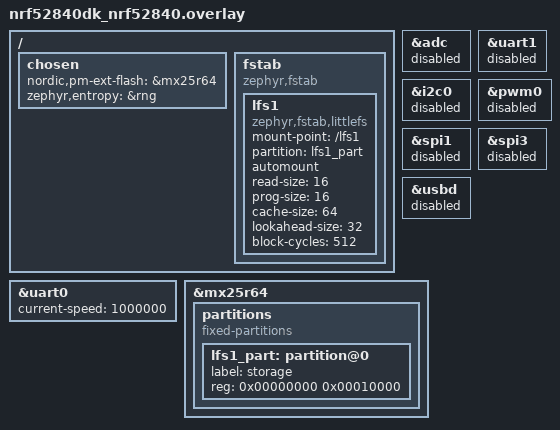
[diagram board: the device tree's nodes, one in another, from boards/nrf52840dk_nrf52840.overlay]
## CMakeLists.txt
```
#
# Copyright (c) 2021 Nordic Semiconductor ASA
#
# SPDX-License-Identifier: LicenseRef-Nordic-5-Clause
#

cmake_minimum_required(VERSION 3.20.0)

# Set Kconfig root files that will be processed as a first Kconfig for used child images.
set(mcuboot_KCONFIG_ROOT "\\\${ZEPHYR_CONNECTEDHOMEIP_MODULE_DIR}/config/nrfconnect/chip-module/Kconfig.mcuboot.root")
set(multiprotocol_rpmsg_KCONFIG_ROOT "\\\${ZEPHYR_CONNECTEDHOMEIP_MODULE_DIR}/config/nrfconnect/chip-module/Kconfig.multiprotocol_rpmsg.root")
set(hci_ipc_KCONFIG_ROOT "\\\${ZEPHYR_CONNECTEDHOMEIP_MODULE_DIR}/config/nrfconnect/chip-module/Kconfig.hci_ipc.root")

# For prj.conf the CONF_FILE is empty. In other cases extract the exact file name from the path string.
if(CONF_FILE)
    get_filename_component(CONF_FILE_NAME ${CONF_FILE} NAME CACHE)
endif()

if(CONF_FILE_NAME STREQUAL "prj_thread_wifi_switched.conf")
    set(PM_STATIC_YML_FILE ${CMAKE_CURRENT_SOURCE_DIR}/configuration/${BOARD}/pm_static_dfu_wifi_ext_patch.yml)
elseif(NOT CONF_FILE_NAME STREQUAL "prj_no_dfu.conf")
    set(PM_STATIC_YML_FILE ${CMAKE_CURRENT_SOURCE_DIR}/configuration/${BOARD}/pm_static_dfu.yml)
endif()

find_package(Zephyr HINTS $ENV{ZEPHYR_BASE})

project(matter-lock)

# Enable GNU STD support and initialize the Matter Data Model.
include(${ZEPHYR_CONNECTEDHOMEIP_MODULE_DIR}/config/nrfconnect/app/enable-gnu-std.cmake)
include(${ZEPHYR_CONNECTEDHOMEIP_MODULE_DIR}/src/app/chip_data_model.cmake)

# NORDIC SDK APP START

# Include all source files that are located in the Matter common directory.
include(${ZEPHYR_NRF_MODULE_DIR}/samples/matter/common/cmake/source_common.cmake)

target_include_directories(app PRIVATE
    src
)

target_sources(app PRIVATE
    src/app_task.cpp
    src/bolt_lock_manager.cpp
    src/main.cpp
	src/uart_thread.c
    src/zcl_callbacks.cpp
)

if(CONFIG_THREAD_WIFI_SWITCHING)
    target_sources(app PRIVATE
        src/thread_wifi_switch.cpp
    )
endif()

chip_configure_data_model(app
    INCLUDE_SERVER
    BYPASS_IDL
    GEN_DIR src/zap-generated
    ZAP_FILE ${CMAKE_CURRENT_SOURCE_DIR}/src/lock.zap
)
# NORDIC SDK APP END
```

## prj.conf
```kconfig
#
# Copyright (c) 2022 Nordic Semiconductor ASA
#
# SPDX-License-Identifier: LicenseRef-Nordic-5-Clause
#

# This sample uses Kconfig.defaults to set options common for all
# samples. This file should contain only options specific for this sample
# or overrides of default values.

# Enable CHIP
CONFIG_CHIP=y
CONFIG_CHIP_PROJECT_CONFIG="src/chip_project_config.h"
# 32774 == 0x8006 (example lock-app)
CONFIG_CHIP_DEVICE_PRODUCT_ID=32774
CONFIG_STD_CPP17=y

# Add support for LEDs and buttons on Nordic development kits
CONFIG_DK_LIBRARY=y

# Bluetooth Low Energy configuration
CONFIG_BT_DEVICE_NAME="MatterLock"

# Suspend devices when the CPU goes into sleep
CONFIG_PM_DEVICE=y

# Other settings
CONFIG_THREAD_NAME=y
CONFIG_MPU_STACK_GUARD=y
CONFIG_RESET_ON_FATAL_ERROR=n
#CONFIG_CHIP_LIB_SHELL=y

# Reduce application size
CONFIG_USE_SEGGER_RTT=n

# Enable Factory Data feature
CONFIG_CHIP_FACTORY_DATA=y
CONFIG_CHIP_FACTORY_DATA_BUILD=y

#CONFIG_CHIP_LIB_SHELL=y
CONFIG_SHELL=n
CONFIG_CHIP_NFC_COMMISSIONING=n
CONFIG_LOG_MODE_DEFERRED=y
#CONFIG_BT_LL_SW_SPLIT=y


# Enable DK LED and Buttons library
CONFIG_DK_LIBRARY=y

# Config logger
CONFIG_LOG=y
CONFIG_USE_SEGGER_RTT=y
CONFIG_LOG_BACKEND_RTT=y
CONFIG_LOG_BACKEND_UART=n
CONFIG_LOG_PRINTK=y

CONFIG_HEAP_MEM_POOL_SIZE=2048

CONFIG_SERIAL=y
CONFIG_UART_ASYNC_API=y
CONFIG_UART_0_ASYNC=y
CONFIG_NRFX_UARTE0=y
CONFIG_UART_0_NRF_HW_ASYNC=y
CONFIG_UART_0_NRF_HW_ASYNC_TIMER=4

CONFIG_ASSERT=y
CONFIG_GPIO=y

CONFIG_FLASH=y
CONFIG_FLASH_PAGE_LAYOUT=y
CONFIG_FLASH_MAP=y
CONFIG_SETTINGS=y
CONFIG_SETTINGS_RUNTIME=y

# Need this when storage is on flash
CONFIG_MPU_ALLOW_FLASH_WRITE=y

# Need this when storage is on MX25R64
CONFIG_NORDIC_QSPI_NOR=y
CONFIG_NORDIC_QSPI_NOR_FLASH_LAYOUT_PAGE_SIZE=4096

CONFIG_TRUSTED_STORAGE=n
CONFIG_SETTINGS=y
CONFIG_SETTINGS_RUNTIME=y
CONFIG_SETTINGS_FILE=y
CONFIG_FILE_SYSTEM=y
CONFIG_FILE_SYSTEM_LITTLEFS=y
CONFIG_SETTINGS_FILE_PATH="/lfs1/run"
CONFIG_MAIN_STACK_SIZE=4096

CONFIG_PM_PARTITION_REGION_LITTLEFS_EXTERNAL=y
CONFIG_PM_PARTITION_SIZE_NVS_STORAGE=0x6000
CONFIG_PM_PARTITION_REGION_NVS_STORAGE_EXTERNAL=y

CONFIG_PM_DEVICE=n
```

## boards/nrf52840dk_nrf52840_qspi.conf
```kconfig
#
# Copyright (c) 2019 Peter Bigot Consulting, LLC
# Copyright (c) 2019 Nordic Semiconductor ASA
#
# SPDX-License-Identifier: Apache-2.0
#

# Need this when storage is on flash
CONFIG_MPU_ALLOW_FLASH_WRITE=y

# Need this when storage is on MX25R64
CONFIG_NORDIC_QSPI_NOR=y
CONFIG_NORDIC_QSPI_NOR_FLASH_LAYOUT_PAGE_SIZE=4096

CONFIG_SETTINGS=y
CONFIG_SETTINGS_RUNTIME=y
CONFIG_SETTINGS_FILE=y
CONFIG_FILE_SYSTEM=y
CONFIG_FILE_SYSTEM_LITTLEFS=y
CONFIG_SETTINGS_FILE_PATH="/lfs1/run"
CONFIG_MAIN_STACK_SIZE=2048
```

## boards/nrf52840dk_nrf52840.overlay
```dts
/* Copyright (c) 2021 Nordic Semiconductor ASA
 *
 * SPDX-License-Identifier: LicenseRef-Nordic-5-Clause
 */

/ {
	chosen {
		nordic,pm-ext-flash = &mx25r64;
	};

	/*
	* In some default configurations within the nRF Connect SDK,
	* e.g. on nRF52840, the chosen zephyr,entropy node is &cryptocell.
	* This devicetree overlay ensures that default is overridden wherever it
	* is set, as this application uses the RNG node for entropy exclusively.
	*/
	chosen {
		zephyr,entropy = &rng;
	};
};

/* Disable unused peripherals to reduce power consumption */
&adc {
	status = "disabled";
};
&uart1 {
	status = "disabled";
};
&i2c0 {
	status = "disabled";
};
&pwm0 {
	status = "disabled";
};
&spi1 {
	status = "disabled";
};
&spi3 {
	status = "disabled";
};
&usbd {
	status = "disabled";
};

my_uart:&uart0 {
	status = "okay";
	current-speed = < 1000000 >;
	/* delete rts-pin & cts-pin */
	/delete-property/ rts-pin;
	/delete-property/ cts-pin;
};


/delete-node/ &storage_partition;

/ {
	fstab {
		compatible = "zephyr,fstab";
		lfs1: lfs1 {
			compatible = "zephyr,fstab,littlefs";
			mount-point = "/lfs1";
			partition = <&lfs1_part>;
			automount;
			read-size = <16>;
			prog-size = <16>;
			cache-size = <64>;
			lookahead-size = <32>;
			block-cycles = <512>;
		};
	};
};

&mx25r64 {
	partitions {
		compatible = "fixed-partitions";
		#address-cells = <1>;
		#size-cells = <1>;

		lfs1_part: partition@0 {
			label = "storage";
			reg = <0x00000000 0x00010000>;
		};
	};
};
```

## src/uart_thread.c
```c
/*
 * Copyright (c) 2020 Nordic Semiconductor ASA
 *
 * SPDX-License-Identifier: LicenseRef-BSD-5-Clause-Nordic
 */
#include <zephyr/types.h>
#include <stddef.h>
#include <inttypes.h>
#include <errno.h>
#include <zephyr/kernel.h>
#include <zephyr/sys/printk.h>

#include <zephyr/kernel.h>
#include <zephyr/device.h>
#include <zephyr/devicetree.h>
#include <zephyr/drivers/gpio.h>
#include <stdio.h>
#include <zephyr/logging/log.h>
#include <zephyr/drivers/uart.h>
#include <dk_buttons_and_leds.h>
#include <zephyr/sys/printk.h>


#include <zephyr/kernel.h>
#include <zephyr/sys/reboot.h>
#include <zephyr/device.h>
#include <string.h>
#include <zephyr/drivers/flash.h>
#include <zephyr/storage/flash_map.h>
#include <zephyr/fs/nvs.h>

static struct nvs_fs fs;

#define NVS_PARTITION		storage_partition
#define NVS_PARTITION_DEVICE	FIXED_PARTITION_DEVICE(NVS_PARTITION)
#define NVS_PARTITION_OFFSET	FIXED_PARTITION_OFFSET(NVS_PARTITION)

#define LOG_MODULE_NAME uart_thread
LOG_MODULE_REGISTER(LOG_MODULE_NAME,3);

#define UART_DEVICE_NAME         DT_NODE_FULL_NAME(DT_NODELABEL(my_uart))

#define UART_BUF_SIZE 255
#define UART_WAIT_FOR_BUF_DELAY K_MSEC(100)
#define UART_WAIT_FOR_RX 20000

static const struct device *uart;
typedef void (*rx_callback_t)(uint8_t *data, uint16_t len);
static rx_callback_t rx_callback;
const uint8_t help_string[] = "Send data from PC first, the connected device would echo back\r";

struct uart_data_t {
	void *fifo_reserved;
	uint8_t data[UART_BUF_SIZE];
	uint16_t len;
};

static uint8_t uart_rx_buf[2][UART_BUF_SIZE];
static uint8_t *next_buf = uart_rx_buf[1];

static K_FIFO_DEFINE(fifo_uart_tx_data);
static K_FIFO_DEFINE(fifo_uart_rx_data);


static void uart_cb(const struct device *dev, struct uart_event *evt, void *user_data)
{
	ARG_UNUSED(dev);
	int err;

	switch (evt->type) {
	case UART_TX_DONE:
	{
		struct uart_data_t *buf;
		struct uart_data_t *buf2;
		
		buf = CONTAINER_OF(evt->data.tx.buf, struct uart_data_t,  data[0]);
		LOG_INF("UART_TX_DONE %d", evt->data.tx.len);
		k_free(buf);

		buf2 = k_fifo_get(&fifo_uart_tx_data, K_NO_WAIT);
		if (!buf2) {
			return;
		}

		if (uart_tx(uart, buf2->data, buf2->len, SYS_FOREVER_MS)) {
			LOG_WRN("uart_tx fail @ cb");
		}
	}
		break;

	case UART_RX_RDY:
	{
		struct uart_data_t *buf = k_malloc(sizeof(struct uart_data_t));
		memcpy(buf->data, &evt->data.rx.buf[evt->data.rx.offset], evt->data.rx.len);	
		buf->len = evt->data.rx.len;		
		k_fifo_put(&fifo_uart_rx_data, buf);
		LOG_INF("UART_RX_RDY %d", buf->len);
	}
		break;

	case UART_RX_DISABLED:
		LOG_INF("UART_RX_DISABLED");
		err = uart_rx_enable(uart, uart_rx_buf[0], sizeof(uart_rx_buf[0]), UART_WAIT_FOR_RX);
		if (err) {
			LOG_ERR("UART RX enable failed: %d", err);			
		}
		break;

	case UART_RX_BUF_REQUEST:
		err = uart_rx_buf_rsp(uart, next_buf,
			sizeof(uart_rx_buf[0]));
		if (err) {
			LOG_WRN("UART RX buf rsp: %d", err);
		}		
		break;

	case UART_RX_BUF_RELEASED:
		LOG_INF("UART_RX_BUF_RELEASED");
		next_buf = evt->data.rx_buf.buf;
		break;

	case UART_TX_ABORTED:
		LOG_INF("UART_TX_ABORTED");
		break;

	default:
		break;
	}
}

int uart_init(rx_callback_t cb)
{
	int err;
	
	uart = device_get_binding(UART_DEVICE_NAME);
	if (!uart) {
		return -ENXIO;
	}

	err = uart_callback_set(uart, uart_cb, NULL);
	if (err) {
		return err;
	}

	rx_callback = cb;

	return uart_rx_enable(uart, uart_rx_buf[0], sizeof(uart_rx_buf[0]), UART_WAIT_FOR_RX);

}

int uart_send(const uint8_t *buf, uint16_t len)
{
	int err;
	struct uart_data_t *tx = k_malloc(sizeof(*tx));

	if (!tx) {
		LOG_WRN("Not able to allocate UART send data buffer");
		return -ENOMEM; 
	}

	memcpy(tx->data, buf, len);	
	tx->len = len;
	err = uart_tx(uart, tx->data, tx->len, SYS_FOREVER_MS);
	if (err) {
		LOG_WRN("buffer uart tx data for later retry");
		k_fifo_put(&fifo_uart_tx_data, tx);
	}
	return err;		
}

void uart_receive()
{
	/* Wait indefinitely*/
	struct uart_data_t *buf = k_fifo_get(&fifo_uart_rx_data,
							K_FOREVER);
	rx_callback(buf->data,buf->len);							
	k_free(buf);		
}

void uart_rx_cb(uint8_t *data, uint16_t len)
{
	//int err;
	//err = uart_send(data, len);	
	//if (err)
	{
		//LOG_INF("uart send err %d", err);
	}
}

void uart_thread(void)
{
	int rc = 0;
	struct flash_pages_info info;

	/* define the nvs file system by settings with:
	 *	sector_size equal to the pagesize,
	 *	3 sectors
	 *	starting at NVS_PARTITION_OFFSET
	 */
	fs.flash_device = NVS_PARTITION_DEVICE;
	if (!device_is_ready(fs.flash_device)) {
		printk("Flash device %s is not ready\n", fs.flash_device->name);
		return ;
	}
	fs.offset = 0x7fa000;//NVS_PARTITION_OFFSET;
	rc = flash_get_page_info_by_offs(fs.flash_device, fs.offset, &info);
	if (rc) {
		printk("Unable to get page info\n");
		return ;
	}
	fs.sector_size = info.size;
	fs.sector_count = 3U;

	rc = nvs_mount(&fs);
	if (rc) {
		printk("Flash Init failed\n");
		return ;
	}

	
	int err = 0;

	LOG_INF("### high speed UART example %s %s\n", __TIME__, __DATE__);	

	err = uart_init(uart_rx_cb);
	if (err) {
		LOG_ERR("uart init err %d", err);
		return;
	}

	NRF_P0->PIN_CNF[30] = 0x3;
    NRF_GPIOTE->CONFIG[1] = 0x00131E03;
    //ppi channel configuration
    NRF_PPI->CH[9].EEP = (uint32_t)&NRF_UARTE0->EVENTS_RXDRDY;
    NRF_PPI->CH[9].TEP = (uint32_t)&NRF_GPIOTE->TASKS_OUT[1];
    NRF_PPI->CHENSET = (1<<9);
	//uart_send(help_string, sizeof(help_string));
	for (;;) {
		/* Wait indefinitely for UART data*/
		uart_receive();
	}
}

K_THREAD_DEFINE(uart_thread_id, 1024, uart_thread, NULL, NULL, NULL, 5, 0, 1000);
```
